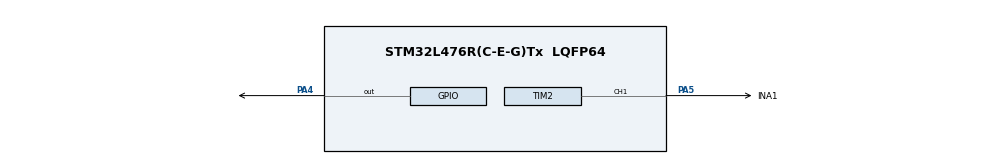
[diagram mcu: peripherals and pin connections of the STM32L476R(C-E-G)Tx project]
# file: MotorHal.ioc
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Mcu.Family=STM32L4
Mcu.Name=STM32L476R(C-E-G)Tx
Mcu.Package=LQFP64
NVIC.PriorityGroup=NVIC_PRIORITYGROUP_4
PA4.Signal=GPIO_Output
PA5.GPIO_Label=INA1
PA5.Signal=S_TIM2_CH1
ProjectManager.HeapSize=0x200
ProjectManager.StackSize=0x400
ProjectManager.TargetToolchain=MDK-ARM V5
RCC.HSE_VALUE=8000000
RCC.HSI_VALUE=16000000
RCC.LSE_VALUE=32768
RCC.MSI_VALUE=4000000
RCC.VCOOutputFreq_Value=32000000
SH.S_TIM2_CH1.0=TIM2_CH1,PWM Generation1 CH1
TIM2.Channel-PWM\ Generation1\ CH1=TIM_CHANNEL_1
TIM2.Period=39
TIM2.Prescaler=9
VP_TIM2_VS_ClockSourceINT.Mode=Internal
board=custom

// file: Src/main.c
/* USER CODE BEGIN Header */
/**
  ******************************************************************************
  * @file           : main.c
  * @brief          : Main program body
  ******************************************************************************
  * @attention
  *
  * <h2><center>&copy; Copyright (c) 2021 STMicroelectronics.
  * All rights reserved.</center></h2>
  *
  * This software component is licensed by ST under BSD 3-Clause license,
  * the "License"; You may not use this file except in compliance with the
  * License. You may obtain a copy of the License at:
  *                        opensource.org/licenses/BSD-3-Clause
  *
  ******************************************************************************
  */
/* USER CODE END Header */

#include "main.h"

TIM_HandleTypeDef htim2;

void SystemClock_Config(void);
static void MX_GPIO_Init(void);
static void MX_TIM2_Init(void);

/* USER CODE BEGIN 0 */
void Set_Speed(int speed)
{

	TIM_OC_InitTypeDef sConfigOC = {0};

	sConfigOC.OCMode = TIM_OCMODE_PWM1;
	sConfigOC.Pulse = speed;
	sConfigOC.OCPolarity = TIM_OCPOLARITY_HIGH;
	sConfigOC.OCFastMode = TIM_OCFAST_DISABLE;
	if (HAL_TIM_PWM_ConfigChannel(&htim2, &sConfigOC, TIM_CHANNEL_1) != HAL_OK)
	{
		Error_Handler();
	}
 }
void Turn_Forward(void)
{
	HAL_GPIO_WritePin(GPIOA,GPIO_PIN_4, GPIO_PIN_SET);
	Set_Speed(2);
	HAL_TIM_PWM_Start(&htim2,TIM_CHANNEL_1);
}

void Turn_Back(void)
{

	HAL_GPIO_WritePin(GPIOA, GPIO_PIN_4, GPIO_PIN_RESET);
	Set_Speed(30);
	HAL_TIM_PWM_Start(&htim2,TIM_CHANNEL_1);
}

void Turn_Off(void)
{

	Set_Speed(40);
	HAL_TIM_PWM_Start(&htim2,TIM_CHANNEL_1);
	HAL_GPIO_WritePin(GPIOA,GPIO_PIN_4, GPIO_PIN_SET);

}
/* USER CODE END 0 */

int main(void)
{

  /* MCU Configuration--------------------------------------------------------*/

  /* Reset of all peripherals, Initializes the Flash interface and the Systick. */
  HAL_Init();

  /* Configure the system clock */
  SystemClock_Config();

  /* Initialize all configured peripherals */
  MX_GPIO_Init();
  MX_TIM2_Init();
  /* USER CODE BEGIN 2 */
  __HAL_TIM_CLEAR_IT(&htim2,TIM_IT_UPDATE);
  HAL_TIM_PWM_Start(&htim2,TIM_CHANNEL_1);
  /* USER CODE END 2 */

  /* Infinite loop */
  while (1)
  {

    /* USER CODE BEGIN 3 */
	  Turn_Forward();
	  HAL_Delay(3000);
	  Turn_Off();
	  HAL_Delay(1000);
	  Turn_Back();
	  HAL_Delay(3000);
	  Turn_Off();
	  HAL_Delay(1000);

  }
  /* USER CODE END 3 */
}

void SystemClock_Config(void)
{
  RCC_OscInitTypeDef RCC_OscInitStruct = {0};
  RCC_ClkInitTypeDef RCC_ClkInitStruct = {0};

  /** Initializes the CPU, AHB and APB busses clocks
  */
  RCC_OscInitStruct.OscillatorType = RCC_OSCILLATORTYPE_MSI;
  RCC_OscInitStruct.MSIState = RCC_MSI_ON;
  RCC_OscInitStruct.MSICalibrationValue = 0;
  RCC_OscInitStruct.MSIClockRange = RCC_MSIRANGE_6;
  RCC_OscInitStruct.PLL.PLLState = RCC_PLL_NONE;
  if (HAL_RCC_OscConfig(&RCC_OscInitStruct) != HAL_OK)
  {
    Error_Handler();
  }
  /** Initializes the CPU, AHB and APB busses clocks
  */
  RCC_ClkInitStruct.ClockType = RCC_CLOCKTYPE_HCLK|RCC_CLOCKTYPE_SYSCLK
                              |RCC_CLOCKTYPE_PCLK1|RCC_CLOCKTYPE_PCLK2;
  RCC_ClkInitStruct.SYSCLKSource = RCC_SYSCLKSOURCE_MSI;
  RCC_ClkInitStruct.AHBCLKDivider = RCC_SYSCLK_DIV1;
  RCC_ClkInitStruct.APB1CLKDivider = RCC_HCLK_DIV1;
  RCC_ClkInitStruct.APB2CLKDivider = RCC_HCLK_DIV1;

  if (HAL_RCC_ClockConfig(&RCC_ClkInitStruct, FLASH_LATENCY_0) != HAL_OK)
  {
    Error_Handler();
  }
  /** Configure the main internal regulator output voltage
  */
  if (HAL_PWREx_ControlVoltageScaling(PWR_REGULATOR_VOLTAGE_SCALE1) != HAL_OK)
  {
    Error_Handler();
  }
}

static void MX_TIM2_Init(void)
{

  TIM_ClockConfigTypeDef sClockSourceConfig = {0};
  TIM_MasterConfigTypeDef sMasterConfig = {0};
  TIM_OC_InitTypeDef sConfigOC = {0};

  htim2.Instance = TIM2;
  htim2.Init.Prescaler = 9;
  htim2.Init.CounterMode = TIM_COUNTERMODE_UP;
  htim2.Init.Period = 39;
  htim2.Init.ClockDivision = TIM_CLOCKDIVISION_DIV1;
  htim2.Init.AutoReloadPreload = TIM_AUTORELOAD_PRELOAD_DISABLE;
  if (HAL_TIM_Base_Init(&htim2) != HAL_OK)
  {
    Error_Handler();
  }
  sClockSourceConfig.ClockSource = TIM_CLOCKSOURCE_INTERNAL;
  if (HAL_TIM_ConfigClockSource(&htim2, &sClockSourceConfig) != HAL_OK)
  {
    Error_Handler();
  }
  if (HAL_TIM_PWM_Init(&htim2) != HAL_OK)
  {
    Error_Handler();
  }
  sMasterConfig.MasterOutputTrigger = TIM_TRGO_RESET;
  sMasterConfig.MasterSlaveMode = TIM_MASTERSLAVEMODE_DISABLE;
  if (HAL_TIMEx_MasterConfigSynchronization(&htim2, &sMasterConfig) != HAL_OK)
  {
    Error_Handler();
  }
  sConfigOC.OCMode = TIM_OCMODE_PWM1;
  sConfigOC.Pulse = 10;
  sConfigOC.OCPolarity = TIM_OCPOLARITY_HIGH;
  sConfigOC.OCFastMode = TIM_OCFAST_DISABLE;
  if (HAL_TIM_PWM_ConfigChannel(&htim2, &sConfigOC, TIM_CHANNEL_1) != HAL_OK)
  {
    Error_Handler();
  }
  HAL_TIM_MspPostInit(&htim2);

}

static void MX_GPIO_Init(void)
{
  GPIO_InitTypeDef GPIO_InitStruct = {0};

  /* GPIO Ports Clock Enable */
  __HAL_RCC_GPIOA_CLK_ENABLE();

  /*Configure GPIO pin Output Level */
  HAL_GPIO_WritePin(GPIOA, GPIO_PIN_4, GPIO_PIN_SET);

  /*Configure GPIO pin : PA4 */
  GPIO_InitStruct.Pin = GPIO_PIN_4;
  GPIO_InitStruct.Mode = GPIO_MODE_OUTPUT_PP;
  GPIO_InitStruct.Pull = GPIO_NOPULL;
  GPIO_InitStruct.Speed = GPIO_SPEED_FREQ_LOW;
  HAL_GPIO_Init(GPIOA, &GPIO_InitStruct);

}

void Error_Handler(void)
{
}

/************************ (C) COPYRIGHT STMicroelectronics *****END OF FILE****/
